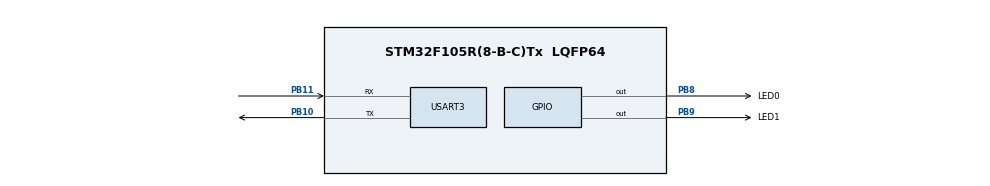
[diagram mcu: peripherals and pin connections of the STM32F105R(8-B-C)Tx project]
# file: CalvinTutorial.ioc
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Mcu.Family=STM32F1
Mcu.Name=STM32F105R(8-B-C)Tx
Mcu.Package=LQFP64
NVIC.PriorityGroup=NVIC_PRIORITYGROUP_4
PB10.Mode=Asynchronous
PB10.Signal=USART3_TX
PB11.Mode=Asynchronous
PB11.Signal=USART3_RX
PB8.GPIO_Label=LED0
PB8.Signal=GPIO_Output
PB9.GPIO_Label=LED1
PB9.Signal=GPIO_Output
ProjectManager.HeapSize=0x200
ProjectManager.StackSize=0x400
ProjectManager.TargetToolchain=STM32CubeIDE
RCC.USBFreq_Value=10666666.666666666
USART3.VirtualMode=VM_ASYNC
VP_SYS_VS_ND.Mode=No_Debug
board=custom

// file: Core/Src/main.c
/* USER CODE BEGIN Header */
/**
 ******************************************************************************
 * @file           : main.c
 * @brief          : Main program body
 ******************************************************************************
 * @attention
 *
 * <h2><center>&copy; Copyright (c) 2021 STMicroelectronics.
 * All rights reserved.</center></h2>
 *
 * This software component is licensed by ST under BSD 3-Clause license,
 * the "License"; You may not use this file except in compliance with the
 * License. You may obtain a copy of the License at:
 *                        opensource.org/licenses/BSD-3-Clause
 *
 ******************************************************************************
 */
/* USER CODE END Header */
#include "main.h"

/* USER CODE BEGIN Includes */
#include <string.h>
#include <stdio.h>

/* USER CODE END Includes */

UART_HandleTypeDef huart3;

void SystemClock_Config(void);
static void MX_GPIO_Init(void);
static void MX_USART3_UART_Init(void);

int main(void)
{

  /* MCU Configuration--------------------------------------------------------*/

  /* Reset of all peripherals, Initializes the Flash interface and the Systick. */
  HAL_Init();

  /* Configure the system clock */
  SystemClock_Config();

  /* Initialize all configured peripherals */
  MX_GPIO_Init();
  MX_USART3_UART_Init();
  /* USER CODE BEGIN 2 */
  char serialMsg[100];
  /* USER CODE END 2 */

  /* Infinite loop */
	while (1) {

    /* USER CODE BEGIN 3 */
		HAL_GPIO_WritePin(GPIOB, LED0_Pin, GPIO_PIN_SET);
		HAL_GPIO_WritePin(GPIOB, LED1_Pin, GPIO_PIN_RESET);
		sprintf(serialMsg, "L0 ON\tL1 OFF\r\n");
		HAL_UART_Transmit(&huart3, (uint8_t*)serialMsg, strlen(serialMsg), HAL_MAX_DELAY);

		HAL_Delay(1000);

		HAL_GPIO_WritePin(GPIOB, LED0_Pin, GPIO_PIN_RESET);
		HAL_GPIO_WritePin(GPIOB, LED1_Pin, GPIO_PIN_SET);
		sprintf(serialMsg, "L0 OFF\tL1 ON\r\n");
		HAL_UART_Transmit(&huart3, (uint8_t*)serialMsg, strlen(serialMsg), HAL_MAX_DELAY);

		HAL_Delay(1000);
	}
  /* USER CODE END 3 */
}

void SystemClock_Config(void)
{
  RCC_OscInitTypeDef RCC_OscInitStruct = {0};
  RCC_ClkInitTypeDef RCC_ClkInitStruct = {0};

  /** Initializes the RCC Oscillators according to the specified parameters
  * in the RCC_OscInitTypeDef structure.
  */
  RCC_OscInitStruct.OscillatorType = RCC_OSCILLATORTYPE_HSI;
  RCC_OscInitStruct.HSIState = RCC_HSI_ON;
  RCC_OscInitStruct.HSICalibrationValue = RCC_HSICALIBRATION_DEFAULT;
  RCC_OscInitStruct.PLL.PLLState = RCC_PLL_NONE;
  RCC_OscInitStruct.PLL2.PLL2State = RCC_PLL_NONE;
  if (HAL_RCC_OscConfig(&RCC_OscInitStruct) != HAL_OK)
  {
    Error_Handler();
  }
  /** Initializes the CPU, AHB and APB buses clocks
  */
  RCC_ClkInitStruct.ClockType = RCC_CLOCKTYPE_HCLK|RCC_CLOCKTYPE_SYSCLK
                              |RCC_CLOCKTYPE_PCLK1|RCC_CLOCKTYPE_PCLK2;
  RCC_ClkInitStruct.SYSCLKSource = RCC_SYSCLKSOURCE_HSI;
  RCC_ClkInitStruct.AHBCLKDivider = RCC_SYSCLK_DIV1;
  RCC_ClkInitStruct.APB1CLKDivider = RCC_HCLK_DIV1;
  RCC_ClkInitStruct.APB2CLKDivider = RCC_HCLK_DIV1;

  if (HAL_RCC_ClockConfig(&RCC_ClkInitStruct, FLASH_LATENCY_0) != HAL_OK)
  {
    Error_Handler();
  }
  /** Configure the Systick interrupt time
  */
  __HAL_RCC_PLLI2S_ENABLE();
}

static void MX_USART3_UART_Init(void)
{

  huart3.Instance = USART3;
  huart3.Init.BaudRate = 115200;
  huart3.Init.WordLength = UART_WORDLENGTH_8B;
  huart3.Init.StopBits = UART_STOPBITS_1;
  huart3.Init.Parity = UART_PARITY_NONE;
  huart3.Init.Mode = UART_MODE_TX_RX;
  huart3.Init.HwFlowCtl = UART_HWCONTROL_NONE;
  huart3.Init.OverSampling = UART_OVERSAMPLING_16;
  if (HAL_UART_Init(&huart3) != HAL_OK)
  {
    Error_Handler();
  }

}

static void MX_GPIO_Init(void)
{
  GPIO_InitTypeDef GPIO_InitStruct = {0};

  /* GPIO Ports Clock Enable */
  __HAL_RCC_GPIOB_CLK_ENABLE();

  /*Configure GPIO pin Output Level */
  HAL_GPIO_WritePin(GPIOB, LED0_Pin|LED1_Pin, GPIO_PIN_RESET);

  /*Configure GPIO pins : LED0_Pin LED1_Pin */
  GPIO_InitStruct.Pin = LED0_Pin|LED1_Pin;
  GPIO_InitStruct.Mode = GPIO_MODE_OUTPUT_PP;
  GPIO_InitStruct.Pull = GPIO_NOPULL;
  GPIO_InitStruct.Speed = GPIO_SPEED_FREQ_LOW;
  HAL_GPIO_Init(GPIOB, &GPIO_InitStruct);

}

void Error_Handler(void)
{
	__disable_irq();
	while (1) {
	}
}

/************************ (C) COPYRIGHT STMicroelectronics *****END OF FILE****/
